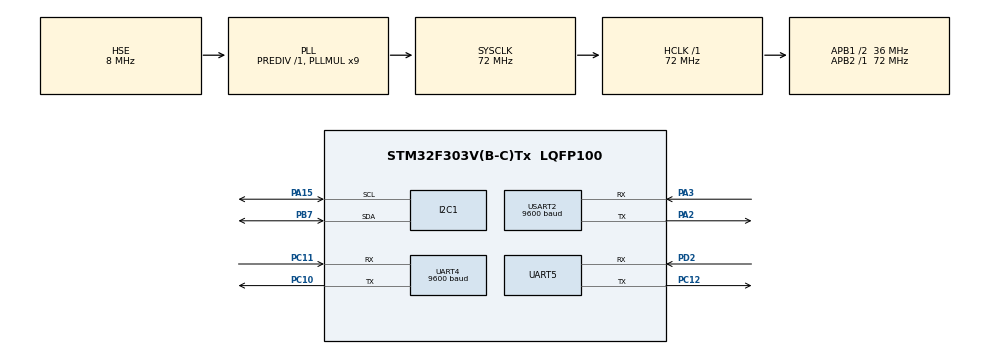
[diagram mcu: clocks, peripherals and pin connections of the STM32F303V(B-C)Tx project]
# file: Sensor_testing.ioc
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Mcu.Family=STM32F3
Mcu.Name=STM32F303V(B-C)Tx
Mcu.Package=LQFP100
NVIC.PriorityGroup=NVIC_PRIORITYGROUP_4
PA13.Mode=Serial_Wire
PA13.Signal=SYS_JTMS-SWDIO
PA14.Mode=Serial_Wire
PA14.Signal=SYS_JTCK-SWCLK
PA15.Mode=I2C
PA15.Signal=I2C1_SCL
PA2.Mode=Asynchronous
PA2.Signal=USART2_TX
PA3.Mode=Asynchronous
PA3.Signal=USART2_RX
PB7.Mode=I2C
PB7.Signal=I2C1_SDA
PC10.Mode=Asynchronous
PC10.Signal=UART4_TX
PC11.Mode=Asynchronous
PC11.Signal=UART4_RX
PC12.Mode=Asynchronous
PC12.Signal=UART5_TX
PD2.Mode=Asynchronous
PD2.Signal=UART5_RX
PF0-OSC_IN.Mode=HSE-External-Oscillator
PF0-OSC_IN.Signal=RCC_OSC_IN
PF1-OSC_OUT.Mode=HSE-External-Oscillator
PF1-OSC_OUT.Signal=RCC_OSC_OUT
ProjectManager.HeapSize=0x200
ProjectManager.StackSize=0x400
ProjectManager.TargetToolchain=STM32CubeIDE
RCC.AHBFreq_Value=72000000
RCC.APB1CLKDivider=RCC_HCLK_DIV2
RCC.APB1Freq_Value=36000000
RCC.APB1TimFreq_Value=72000000
RCC.APB2Freq_Value=72000000
RCC.APB2TimFreq_Value=72000000
RCC.CortexFreq_Value=72000000
RCC.HCLKFreq_Value=72000000
RCC.HSE_VALUE=8000000
RCC.HSI_VALUE=8000000
RCC.LSE_VALUE=32768
RCC.PLLMUL=RCC_PLL_MUL9
RCC.PLLSourceVirtual=RCC_PLLSOURCE_HSE
RCC.SYSCLKFreq_VALUE=72000000
RCC.SYSCLKSourceVirtual=RCC_SYSCLKSOURCE_PLLCLK
RCC.USBFreq_Value=72000000
UART4.BaudRate=9600
USART2.BaudRate=9600
USART2.VirtualMode-Asynchronous=VM_ASYNC
board=custom

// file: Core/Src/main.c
/* USER CODE BEGIN Header */
/**
  ******************************************************************************
  * @file           : main.c
  * @brief          : Main program body
  ******************************************************************************
  * @attention
  *
  * Copyright (c) 2024 STMicroelectronics.
  * All rights reserved.
  *
  * This software is licensed under terms that can be found in the LICENSE file
  * in the root directory of this software component.
  * If no LICENSE file comes with this software, it is provided AS-IS.
  *
  ******************************************************************************
  */
/* USER CODE END Header */
#include "main.h"

/* USER CODE BEGIN Includes */
#include "DF_ROBOT_GAS.h"
/* USER CODE END Includes */

/* USER CODE BEGIN PD */
//#define O3_ADDR (0x74 << 1) // ADDRESS_O3: 0x74, A0=0, A1=0
//#define NO2_ADDR (0x75 << 1) // ADDRESS_NO3: 0x75, A0=0, A1=1
//#define CO_ADDR (0x76 << 1) // ADDRESS_CO: 0x76, A0=1, A1=0
/* USER CODE END PD */

I2C_HandleTypeDef hi2c1;

UART_HandleTypeDef huart4;
UART_HandleTypeDef huart5;
UART_HandleTypeDef huart2;

/* USER CODE BEGIN PV */

/************************* Command ***************************/

//uint8_t Active_Sending_mode[9] = {0xFF,0x86,0,0,0,0,0,0,0x7A};
//uint8_t Read_concentration_value[9] = {0xFF,0x01,0x86,0x0,0x0,0x0,0x0,0x0,0x79};
//uint8_t Switch_Mode[9] = {0xFF,0x01,0x78,0x04,0x00,0x00,0x00,0x00,0x84};

/************************* Command ***************************/
//uint8_t Read_concentration_cmd[9] = {0xFF, 0x01, 0x86, 0, 0, 0, 0, 0, 0x79};
//uint8_t sensorData[9];
uint8_t O3_PPM, NO2_PPM, CO_PPM;
//float extractConcentration(uint8_t *data,float multiplier);
//void readSensorData(uint16_t addr, float *ppm,float multiplier);

//uint8_t RxData[9];
//int high_byte_O3;
//int high_byte_NO2;
//int high_byte_CO;
//int low_byte_O3;
//int low_byte_NO2;
//int low_byte_CO;
//float O3_PPM,NO2_PPM,CO_PPM;

//uint8_t O3_Data[9];
//
//int8_t CO_Data[9];
//
//int8_t NO2_Data[9];

/* USER CODE END PV */

void SystemClock_Config(void);
static void MX_GPIO_Init(void);
static void MX_UART4_Init(void);
static void MX_UART5_Init(void);
static void MX_USART2_UART_Init(void);
static void MX_I2C1_Init(void);

/* USER CODE BEGIN 0 */
//float extractConcentration(uint8_t *data, float multiplier) {
//    int high_byte = data[2];
//    int low_byte = data[3];
//    return ((high_byte << 8) | low_byte) * multiplier;
//}
//
//void readSensorData(uint16_t addr, float *ppm, float multiplier) {
//    uint8_t sensorData[9];
//    if (HAL_I2C_Master_Transmit(&hi2c1, addr, Read_concentration_cmd, sizeof(Read_concentration_cmd), 1000) == HAL_OK) {
//        HAL_Delay(10); // Short delay before receiving to give sensor time to prepare data
//        if (HAL_I2C_Master_Receive(&hi2c1, addr, sensorData, sizeof(sensorData), 1000) == HAL_OK) {
//            if (sensorData[0] == 0xFF && sensorData[1] == 0x86) {
//                *ppm = extractConcentration(sensorData, multiplier);
//            }
//        }
//    }
//}
/* USER CODE END 0 */

int main(void)
{

  /* MCU Configuration--------------------------------------------------------*/

  /* Reset of all peripherals, Initializes the Flash interface and the Systick. */
  HAL_Init();

  /* Configure the system clock */
  SystemClock_Config();

  /* Initialize all configured peripherals */
  MX_GPIO_Init();
  MX_UART4_Init();
  MX_UART5_Init();
  MX_USART2_UART_Init();
  MX_I2C1_Init();

  /* Infinite loop */
  while (1)
  {

    /* USER CODE BEGIN 3 */

      readSensorData(O3_ADDR, &O3_PPM,0.1);
      readSensorData(NO2_ADDR, &NO2_PPM,0.1);
      readSensorData(CO_ADDR, &CO_PPM,1.0);
      HAL_Delay(1000);

//	  HAL_I2C_Master_Transmit(&hi2c1, O3 << 1, Read_concentration_value, sizeof(Read_concentration_value), HAL_MAX_DELAY);
//
//	 if( HAL_I2C_Master_Receive(&hi2c1, O3 << 1,O3_Data,sizeof(O3_Data), HAL_MAX_DELAY) == HAL_OK{
//	  	        // Check if the response is valid
//	  	        if (O3_Data[0] == 0xFF && O3_Data[1] == 0x86) {
//	  	            high_byte = O3_Data[2];
//	  	            low_byte = O3_Data[3];
////	  	            concentration = ((high_byte * 256) + low_byte);
//	  	        concentration = ((high_byte * 256) + low_byte)*0.1;
//	  	        }
//	  	    }
//
//	  	    HAL_Delay(1000);  // Delay between requests

//	  HAL_UART_Transmit(&huart2,Read_concentration_value,sizeof(Read_concentration_value), HAL_MAX_DELAY);
//	  HAL_UART_Transmit(&huart2,Switch_Mode,sizeof(Switch_Mode), HAL_MAX_DELAY);
//
//	    if (HAL_UART_Receive(&huart2, RxData, sizeof(RxData), 1000) == HAL_OK) {
//	        // Check if the response is valid
//	        if (RxData[0] == 0xFF && RxData[1] == 0x86) {
//	            high_byte = RxData[2];
//	            low_byte = RxData[3];
//	            concentration = ((high_byte * 256) + low_byte);
//	            concentration = ((high_byte * 256) + low_byte)*0.1;
//	        }
//	    }
//
//	    HAL_Delay(1000);  // Delay between requests

  }
  /* USER CODE END 3 */
}

void SystemClock_Config(void)
{
  RCC_OscInitTypeDef RCC_OscInitStruct = {0};
  RCC_ClkInitTypeDef RCC_ClkInitStruct = {0};
  RCC_PeriphCLKInitTypeDef PeriphClkInit = {0};

  /** Initializes the RCC Oscillators according to the specified parameters
  * in the RCC_OscInitTypeDef structure.
  */
  RCC_OscInitStruct.OscillatorType = RCC_OSCILLATORTYPE_HSI|RCC_OSCILLATORTYPE_HSE;
  RCC_OscInitStruct.HSEState = RCC_HSE_ON;
  RCC_OscInitStruct.HSEPredivValue = RCC_HSE_PREDIV_DIV1;
  RCC_OscInitStruct.HSIState = RCC_HSI_ON;
  RCC_OscInitStruct.HSICalibrationValue = RCC_HSICALIBRATION_DEFAULT;
  RCC_OscInitStruct.PLL.PLLState = RCC_PLL_ON;
  RCC_OscInitStruct.PLL.PLLSource = RCC_PLLSOURCE_HSE;
  RCC_OscInitStruct.PLL.PLLMUL = RCC_PLL_MUL9;
  if (HAL_RCC_OscConfig(&RCC_OscInitStruct) != HAL_OK)
  {
    Error_Handler();
  }

  /** Initializes the CPU, AHB and APB buses clocks
  */
  RCC_ClkInitStruct.ClockType = RCC_CLOCKTYPE_HCLK|RCC_CLOCKTYPE_SYSCLK
                              |RCC_CLOCKTYPE_PCLK1|RCC_CLOCKTYPE_PCLK2;
  RCC_ClkInitStruct.SYSCLKSource = RCC_SYSCLKSOURCE_PLLCLK;
  RCC_ClkInitStruct.AHBCLKDivider = RCC_SYSCLK_DIV1;
  RCC_ClkInitStruct.APB1CLKDivider = RCC_HCLK_DIV2;
  RCC_ClkInitStruct.APB2CLKDivider = RCC_HCLK_DIV1;

  if (HAL_RCC_ClockConfig(&RCC_ClkInitStruct, FLASH_LATENCY_2) != HAL_OK)
  {
    Error_Handler();
  }
  PeriphClkInit.PeriphClockSelection = RCC_PERIPHCLK_USART2|RCC_PERIPHCLK_UART4
                              |RCC_PERIPHCLK_UART5|RCC_PERIPHCLK_I2C1;
  PeriphClkInit.Usart2ClockSelection = RCC_USART2CLKSOURCE_PCLK1;
  PeriphClkInit.Uart4ClockSelection = RCC_UART4CLKSOURCE_PCLK1;
  PeriphClkInit.Uart5ClockSelection = RCC_UART5CLKSOURCE_PCLK1;
  PeriphClkInit.I2c1ClockSelection = RCC_I2C1CLKSOURCE_HSI;
  if (HAL_RCCEx_PeriphCLKConfig(&PeriphClkInit) != HAL_OK)
  {
    Error_Handler();
  }
}

static void MX_I2C1_Init(void)
{

  hi2c1.Instance = I2C1;
  hi2c1.Init.Timing = 0x2000090E;
  hi2c1.Init.OwnAddress1 = 0;
  hi2c1.Init.AddressingMode = I2C_ADDRESSINGMODE_7BIT;
  hi2c1.Init.DualAddressMode = I2C_DUALADDRESS_DISABLE;
  hi2c1.Init.OwnAddress2 = 0;
  hi2c1.Init.OwnAddress2Masks = I2C_OA2_NOMASK;
  hi2c1.Init.GeneralCallMode = I2C_GENERALCALL_DISABLE;
  hi2c1.Init.NoStretchMode = I2C_NOSTRETCH_DISABLE;
  if (HAL_I2C_Init(&hi2c1) != HAL_OK)
  {
    Error_Handler();
  }

  /** Configure Analogue filter
  */
  if (HAL_I2CEx_ConfigAnalogFilter(&hi2c1, I2C_ANALOGFILTER_ENABLE) != HAL_OK)
  {
    Error_Handler();
  }

  /** Configure Digital filter
  */
  if (HAL_I2CEx_ConfigDigitalFilter(&hi2c1, 0) != HAL_OK)
  {
    Error_Handler();
  }

}

static void MX_UART4_Init(void)
{

  huart4.Instance = UART4;
  huart4.Init.BaudRate = 9600;
  huart4.Init.WordLength = UART_WORDLENGTH_8B;
  huart4.Init.StopBits = UART_STOPBITS_1;
  huart4.Init.Parity = UART_PARITY_NONE;
  huart4.Init.Mode = UART_MODE_TX_RX;
  huart4.Init.HwFlowCtl = UART_HWCONTROL_NONE;
  huart4.Init.OverSampling = UART_OVERSAMPLING_16;
  huart4.Init.OneBitSampling = UART_ONE_BIT_SAMPLE_DISABLE;
  huart4.AdvancedInit.AdvFeatureInit = UART_ADVFEATURE_NO_INIT;
  if (HAL_UART_Init(&huart4) != HAL_OK)
  {
    Error_Handler();
  }

}

static void MX_UART5_Init(void)
{

  huart5.Instance = UART5;
  huart5.Init.BaudRate = 115200;
  huart5.Init.WordLength = UART_WORDLENGTH_8B;
  huart5.Init.StopBits = UART_STOPBITS_1;
  huart5.Init.Parity = UART_PARITY_NONE;
  huart5.Init.Mode = UART_MODE_TX_RX;
  huart5.Init.HwFlowCtl = UART_HWCONTROL_NONE;
  huart5.Init.OverSampling = UART_OVERSAMPLING_16;
  huart5.Init.OneBitSampling = UART_ONE_BIT_SAMPLE_DISABLE;
  huart5.AdvancedInit.AdvFeatureInit = UART_ADVFEATURE_NO_INIT;
  if (HAL_UART_Init(&huart5) != HAL_OK)
  {
    Error_Handler();
  }

}

static void MX_USART2_UART_Init(void)
{

  huart2.Instance = USART2;
  huart2.Init.BaudRate = 9600;
  huart2.Init.WordLength = UART_WORDLENGTH_8B;
  huart2.Init.StopBits = UART_STOPBITS_1;
  huart2.Init.Parity = UART_PARITY_NONE;
  huart2.Init.Mode = UART_MODE_TX_RX;
  huart2.Init.HwFlowCtl = UART_HWCONTROL_NONE;
  huart2.Init.OverSampling = UART_OVERSAMPLING_16;
  huart2.Init.OneBitSampling = UART_ONE_BIT_SAMPLE_DISABLE;
  huart2.AdvancedInit.AdvFeatureInit = UART_ADVFEATURE_NO_INIT;
  if (HAL_UART_Init(&huart2) != HAL_OK)
  {
    Error_Handler();
  }

}

static void MX_GPIO_Init(void)
{

  /* GPIO Ports Clock Enable */
  __HAL_RCC_GPIOF_CLK_ENABLE();
  __HAL_RCC_GPIOA_CLK_ENABLE();
  __HAL_RCC_GPIOC_CLK_ENABLE();
  __HAL_RCC_GPIOD_CLK_ENABLE();
  __HAL_RCC_GPIOB_CLK_ENABLE();

}

void Error_Handler(void)
{
  __disable_irq();
  while (1)
  {
  }
}
